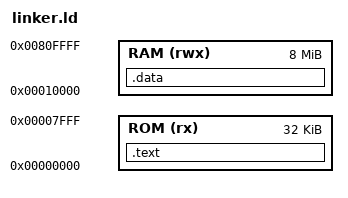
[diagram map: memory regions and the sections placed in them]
MEMORY
{
    ROM (rx)  : ORIGIN = 0x00000000, LENGTH = 32K
    RAM (rwx) : ORIGIN = 0x00010000, LENGTH = 8M
}

SECTIONS
{
    .text : {
        *(.text.init)
        *(.text*)
        *(.rodata*)
    } > ROM

    .data : {
        *(.data*)
        *(.bss*)
        *(COMMON)
    } > RAM
}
